VERSION "pitwall.dbc 3.0 — AIM MXP SmartyCam Enhanced CAN Protocol"

NS_ :

BS_:

BU_: DASH AIM ECU

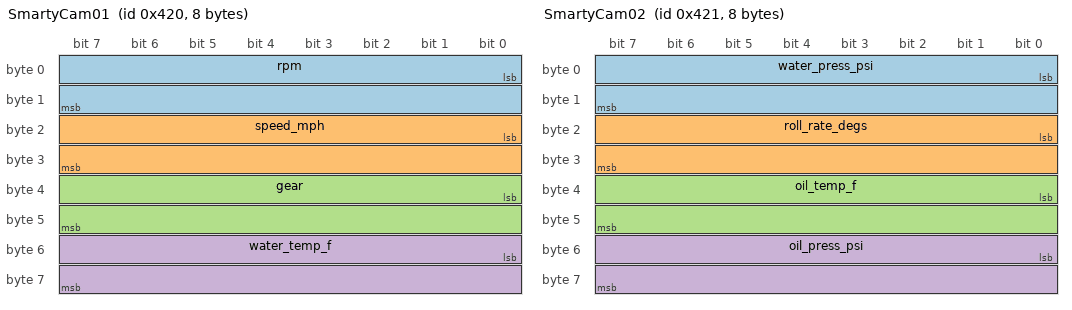
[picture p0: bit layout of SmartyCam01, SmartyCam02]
BO_ 1056 SmartyCam01: 8 AIM
 SG_ rpm : 0|16@1+ (1,0) [0|20000] "rpm" DASH
 SG_ speed_mph : 16|16@1+ (0.1,0) [0|650] "mph" DASH
 SG_ gear : 32|16@1+ (1,0) [-1|8] "gear" DASH
 SG_ water_temp_f : 48|16@1+ (0.1,0) [0|300] "F" DASH

BO_ 1057 SmartyCam02: 8 AIM
 SG_ water_press_psi : 0|16@1+ (0.1,0) [0|100] "psi" DASH
 SG_ roll_rate_degs : 16|16@1- (0.1,0) [-3276|3276] "deg/s" DASH
 SG_ oil_temp_f : 32|16@1+ (0.1,0) [0|400] "F" DASH
 SG_ oil_press_psi : 48|16@1+ (0.1,0) [0|200] "psi" DASH

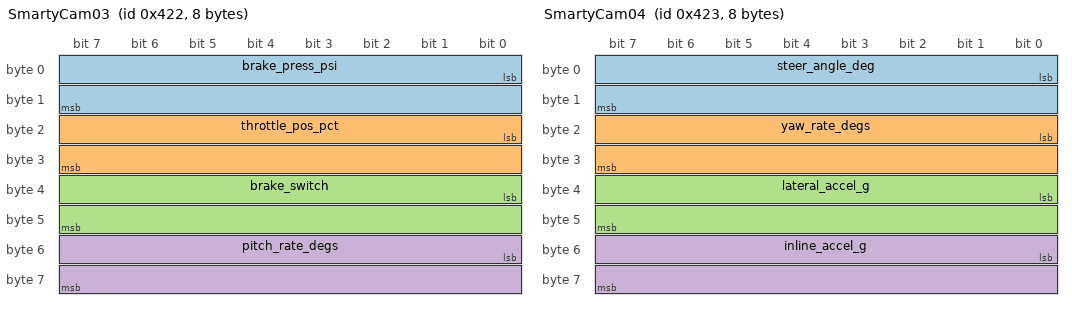
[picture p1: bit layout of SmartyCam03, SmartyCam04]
BO_ 1058 SmartyCam03: 8 AIM
 SG_ brake_press_psi : 0|16@1+ (1,0) [0|2000] "psi" DASH
 SG_ throttle_pos_pct : 16|16@1+ (0.01,0) [0|100] "%" DASH
 SG_ brake_switch : 32|16@1+ (1,0) [0|1] "binary" DASH
 SG_ pitch_rate_degs : 48|16@1- (0.1,0) [-3276|3276] "deg/s" DASH

BO_ 1059 SmartyCam04: 8 AIM
 SG_ steer_angle_deg : 0|16@1- (0.1,0) [-3276|3276] "deg" DASH
 SG_ yaw_rate_degs : 16|16@1- (0.1,0) [-3276|3276] "deg/s" DASH
 SG_ lateral_accel_g : 32|16@1- (0.01,0) [-32|32] "g" DASH
 SG_ inline_accel_g : 48|16@1- (0.01,0) [-32|32] "g" DASH

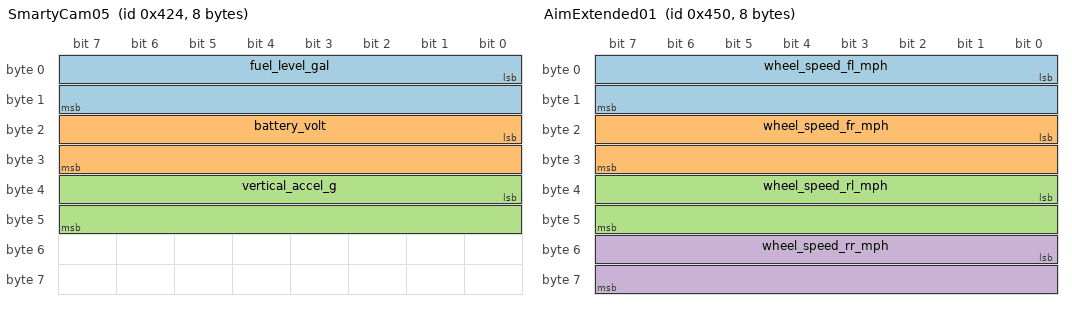
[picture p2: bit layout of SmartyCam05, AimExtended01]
BO_ 1060 SmartyCam05: 8 AIM
 SG_ fuel_level_gal : 0|16@1+ (0.01,0) [0|100] "gal" DASH
 SG_ battery_volt : 16|16@1+ (0.1,0) [0|30] "V" DASH
 SG_ vertical_accel_g : 32|16@1- (0.01,0) [-32|32] "g" DASH

BO_ 1104 AimExtended01: 8 AIM
 SG_ wheel_speed_fl_mph : 0|16@1+ (0.1,0) [0|650] "mph" DASH
 SG_ wheel_speed_fr_mph : 16|16@1+ (0.1,0) [0|650] "mph" DASH
 SG_ wheel_speed_rl_mph : 32|16@1+ (0.1,0) [0|650] "mph" DASH
 SG_ wheel_speed_rr_mph : 48|16@1+ (0.1,0) [0|650] "mph" DASH

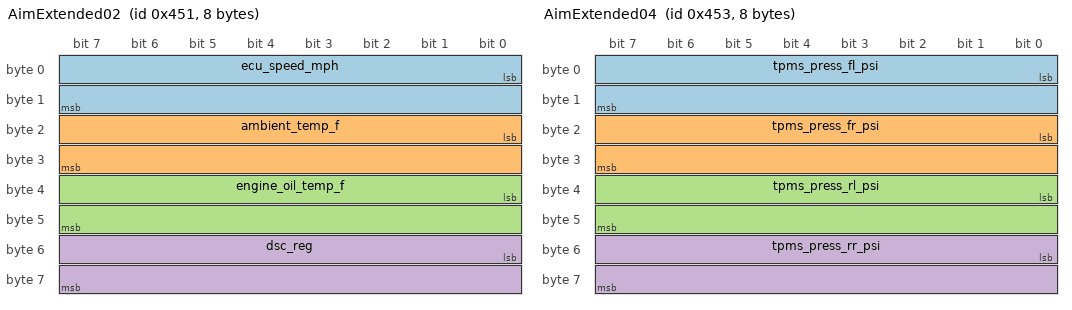
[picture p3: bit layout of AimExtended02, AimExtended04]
BO_ 1105 AimExtended02: 8 AIM
 SG_ ecu_speed_mph : 0|16@1+ (0.1,0) [0|650] "mph" DASH
 SG_ ambient_temp_f : 16|16@1+ (0.1,0) [0|200] "F" DASH
 SG_ engine_oil_temp_f : 32|16@1+ (0.1,0) [0|400] "F" DASH
 SG_ dsc_reg : 48|16@1+ (1,0) [0|1] "binary" DASH

BO_ 1106 AimExtended03: 8 AIM
 SG_ gps_lat : 0|32@1- (1e-7,0) [-90|90] "deg" DASH
 SG_ gps_lon : 32|32@1- (1e-7,0) [-180|180] "deg" DASH

BO_ 1107 AimExtended04: 8 AIM
 SG_ tpms_press_fl_psi : 0|16@1+ (0.1,0) [0|100] "psi" DASH
 SG_ tpms_press_fr_psi : 16|16@1+ (0.1,0) [0|100] "psi" DASH
 SG_ tpms_press_rl_psi : 32|16@1+ (0.1,0) [0|100] "psi" DASH
 SG_ tpms_press_rr_psi : 48|16@1+ (0.1,0) [0|100] "psi" DASH

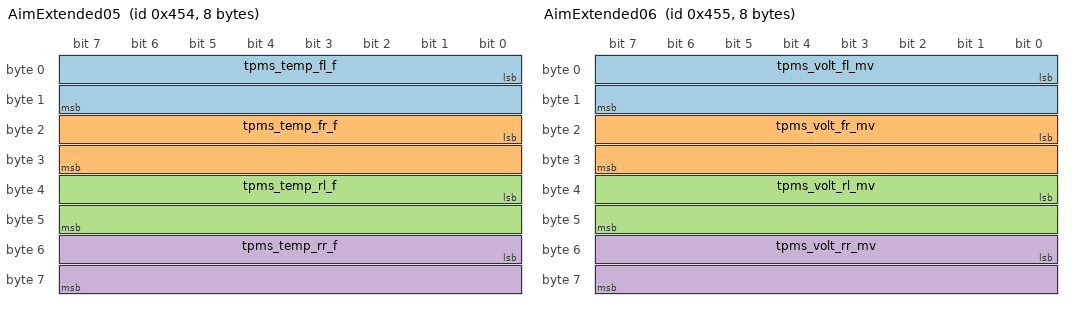
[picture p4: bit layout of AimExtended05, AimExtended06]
BO_ 1108 AimExtended05: 8 AIM
 SG_ tpms_temp_fl_f : 0|16@1+ (0.1,0) [0|400] "F" DASH
 SG_ tpms_temp_fr_f : 16|16@1+ (0.1,0) [0|400] "F" DASH
 SG_ tpms_temp_rl_f : 32|16@1+ (0.1,0) [0|400] "F" DASH
 SG_ tpms_temp_rr_f : 48|16@1+ (0.1,0) [0|400] "F" DASH

BO_ 1109 AimExtended06: 8 AIM
 SG_ tpms_volt_fl_mv : 0|16@1+ (1,0) [0|5000] "mV" DASH
 SG_ tpms_volt_fr_mv : 16|16@1+ (1,0) [0|5000] "mV" DASH
 SG_ tpms_volt_rl_mv : 32|16@1+ (1,0) [0|5000] "mV" DASH
 SG_ tpms_volt_rr_mv : 48|16@1+ (1,0) [0|5000] "mV" DASH

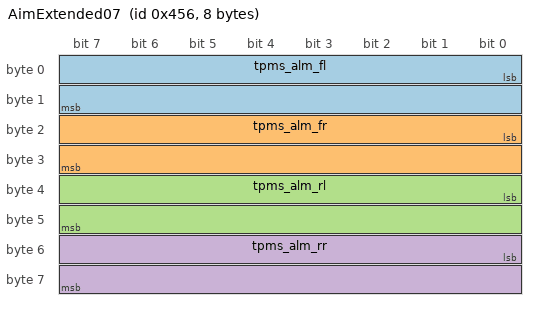
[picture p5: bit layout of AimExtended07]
BO_ 1110 AimExtended07: 8 AIM
 SG_ tpms_alm_fl : 0|16@1+ (1,0) [0|65535] "bitfield" DASH
 SG_ tpms_alm_fr : 16|16@1+ (1,0) [0|65535] "bitfield" DASH
 SG_ tpms_alm_rl : 32|16@1+ (1,0) [0|65535] "bitfield" DASH
 SG_ tpms_alm_rr : 48|16@1+ (1,0) [0|65535] "bitfield" DASH

CM_ "AIM MXP SmartyCam Enhanced CAN Protocol v3.0 Database";
CM_ BO_ 1056 "Standard SmartyCam Message 1: Core Engine/GPS";
CM_ BO_ 1057 "Standard SmartyCam Message 2: Temps & Roll Rate";
CM_ BO_ 1058 "Standard SmartyCam Message 3: Driver Inputs & Pitch Rate";
CM_ BO_ 1059 "Standard SmartyCam Message 4: Dynamics & Yaw Rate";
CM_ BO_ 1060 "Standard SmartyCam Message 5: Vehicle State & Vertical Accel";
CM_ BO_ 1104 "Extended Message: Individual Wheel Speeds";
CM_ BO_ 1105 "Extended Message: ECU Reference Data";
CM_ BO_ 1106 "Extended Message: High-Res GPS";
CM_ BO_ 1107 "Extended Message: TPMS Pressures";
CM_ BO_ 1108 "Extended Message: TPMS Temperatures";
CM_ BO_ 1109 "Extended Message: TPMS Voltages";
CM_ BO_ 1110 "Extended Message: TPMS Alarms";

CM_ SG_ 1057 roll_rate_degs "Overrides Exhaust Temp slot. Signed.";
CM_ SG_ 1058 pitch_rate_degs "Overrides Clutch Pos slot. Signed.";
CM_ SG_ 1059 yaw_rate_degs "Overrides Lambda slot. Signed.";
CM_ SG_ 1059 lateral_accel_g "Lateral Acceleration. Signed.";
CM_ SG_ 1059 inline_accel_g "Longitudinal Acceleration. Signed.";
CM_ SG_ 1060 vertical_accel_g "Vertical Acceleration. Signed.";
CM_ SG_ 1106 gps_lat "Decimal degrees * 1e7. Signed for West/South hemispheres.";
CM_ SG_ 1106 gps_lon "Decimal degrees * 1e7. Signed for West/South hemispheres.";
CM_ SG_ 1110 tpms_alm_fl "Bitfield: 0x01=air leak, 0x10=low temp, 0x20=sensor fail.";
